# nrf54lv10a_enga_application register map
Vendor: Nordic Semiconductor; Series: nrf54l; File version: 1
CPU: CM33 r0p4, little endian, MPU, FPU, 3 interrupt priority bits, 270 interrupts, 4 SAU regions
Registers are 32-bit, read-write, reset 0x0 unless marked. A register's access mark holds for its fields unless they carry their own. Offsets are from the block's base; [hi:lo] are bit positions; lines under a group give offsets from that group; {n}, {i} and the like mark numbered series; 'fields as' and 'values as' point back to an identical list.

## GLOBAL_RRAMC_S — RRAM controller GLITCH detector
Base 0x5004E000; alternate view of GLOBAL_GLITCHDET_S
0x00 TASKS_WAKEUP wo — Wakeup the RRAM from low power mode
  [0] TASKS_WAKEUP
    1=Trigger task
0x04 TASKS_CLRWRITEBUF wo — Clear internal write-buffer
  [0] TASKS_CLRWRITEBUF
    1=Trigger task
0x08 TASKS_COMMITWRITEBUF wo — Commits the data stored in internal write-buffer to RRAM
  [0] TASKS_COMMITWRITEBUF
    1=Trigger task
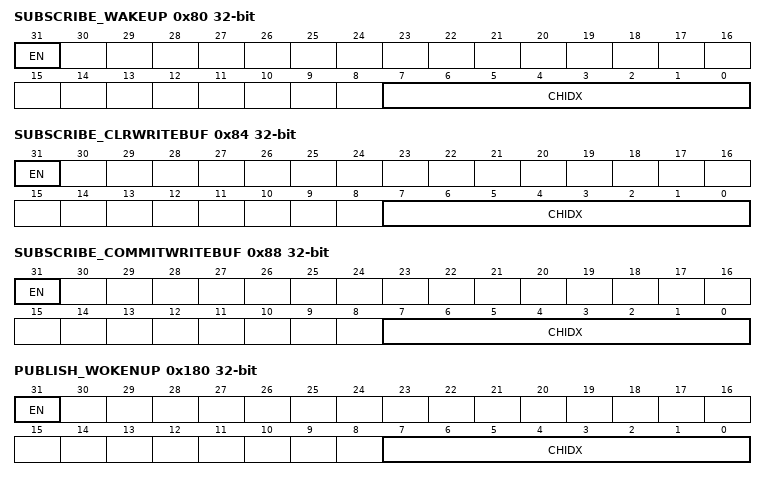
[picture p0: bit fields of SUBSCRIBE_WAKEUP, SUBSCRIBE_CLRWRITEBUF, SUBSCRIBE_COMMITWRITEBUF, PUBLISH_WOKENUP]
0x80 SUBSCRIBE_WAKEUP — Subscribe configuration for task WAKEUP
  [31] EN
    0=Disabled (Disable subscription); 1=Enabled (Enable subscription)
  [7:0] CHIDX — DPPI channel that task WAKEUP will subscribe to
0x84 SUBSCRIBE_CLRWRITEBUF — Subscribe configuration for task CLRWRITEBUF
  [31] EN
    values as SUBSCRIBE_WAKEUP.EN
  [7:0] CHIDX — DPPI channel that task CLRWRITEBUF will subscribe to
0x88 SUBSCRIBE_COMMITWRITEBUF — Subscribe configuration for task COMMITWRITEBUF
  [31] EN
    values as SUBSCRIBE_WAKEUP.EN
  [7:0] CHIDX — DPPI channel that task COMMITWRITEBUF will subscribe to
0x100 EVENTS_WOKENUP — RRAMC is woken up from low power mode
  [0] EVENTS_WOKENUP
    0=NotGenerated (Event not generated); 1=Generated (Event generated)
0x104 EVENTS_READY — RRAMC is ready
  [0] EVENTS_READY
    values as EVENTS_WOKENUP.EVENTS_WOKENUP
0x108 EVENTS_READYNEXT — Ready to accept a new write operation
  [0] EVENTS_READYNEXT
    values as EVENTS_WOKENUP.EVENTS_WOKENUP
0x10C EVENTS_ACCESSERROR — RRAM access error
  [0] EVENTS_ACCESSERROR
    values as EVENTS_WOKENUP.EVENTS_WOKENUP
0x114 EVENTS_ECCERRORCORR — ECC error detected and corrected
  [0] EVENTS_ECCERRORCORR
    values as EVENTS_WOKENUP.EVENTS_WOKENUP
0x180 PUBLISH_WOKENUP — Publish configuration for event WOKENUP
  [31] EN
    0=Disabled (Disable publishing); 1=Enabled (Enable publishing)
  [7:0] CHIDX — DPPI channel that event WOKENUP will publish to
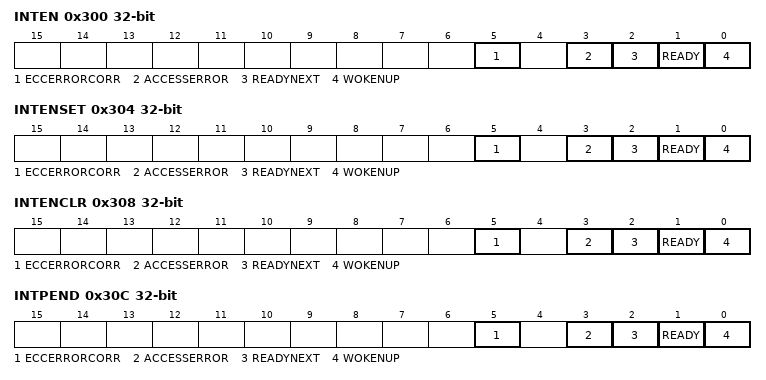
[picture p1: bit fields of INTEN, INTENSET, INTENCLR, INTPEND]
0x300 INTEN — Enable or disable interrupt
  [all] fields
    0=Disabled; 1=Enabled
  [5] ECCERRORCORR — Enable or disable interrupt for event ECCERRORCORR
  [3] ACCESSERROR — Enable or disable interrupt for event ACCESSERROR
  [2] READYNEXT — Enable or disable interrupt for event READYNEXT
  [1] READY — Enable or disable interrupt for event READY
  [0] WOKENUP — Enable or disable interrupt for event WOKENUP
0x304 INTENSET — Enable interrupt
  [all] fields
    on read: 0=Disabled (Read: Disabled); 1=Enabled (Read: Enabled) | on write: 1=Set (Enable)
  [5] ECCERRORCORR — Write '1' to enable interrupt for event ECCERRORCORR
  [3] ACCESSERROR — Write '1' to enable interrupt for event ACCESSERROR
  [2] READYNEXT — Write '1' to enable interrupt for event READYNEXT
  [1] READY — Write '1' to enable interrupt for event READY
  [0] WOKENUP — Write '1' to enable interrupt for event WOKENUP
0x308 INTENCLR — Disable interrupt
  [all] fields
    on read: 0=Disabled (Read: Disabled); 1=Enabled (Read: Enabled) | on write: 1=Clear (Disable)
  [5] ECCERRORCORR — Write '1' to disable interrupt for event ECCERRORCORR
  [3] ACCESSERROR — Write '1' to disable interrupt for event ACCESSERROR
  [2] READYNEXT — Write '1' to disable interrupt for event READYNEXT
  [1] READY — Write '1' to disable interrupt for event READY
  [0] WOKENUP — Write '1' to disable interrupt for event WOKENUP
0x30C INTPEND ro — Pending interrupts
  [all] fields
    on read: 0=NotPending (Read: Not pending); 1=Pending (Read: Pending)
  [5] ECCERRORCORR — Read pending status of interrupt for event ECCERRORCORR
  [3] ACCESSERROR — Read pending status of interrupt for event ACCESSERROR
  [2] READYNEXT — Read pending status of interrupt for event READYNEXT
  [1] READY — Read pending status of interrupt for event READY
  [0] WOKENUP — Read pending status of interrupt for event WOKENUP
0x400 READY ro — RRAMC ready status
  [0] READY — RRAMC is ready or busy
    0=Busy (RRAMC is busy); 1=Ready (The current RRAMC operation is completed and RRAMC is ready)
0x404 READYNEXT ro — Ready next flag
  [0] READYNEXT — RRAMC can accept a new write operation
    0=Busy (RRAMC cannot accept any write operation now); 1=Ready (RRAMC is ready to accept a new write operation)
0x408 ACCESSERRORADDR ro reset 0xFFFFFF — Address of the first access error
  [31:0] ADDRESS — Access error address
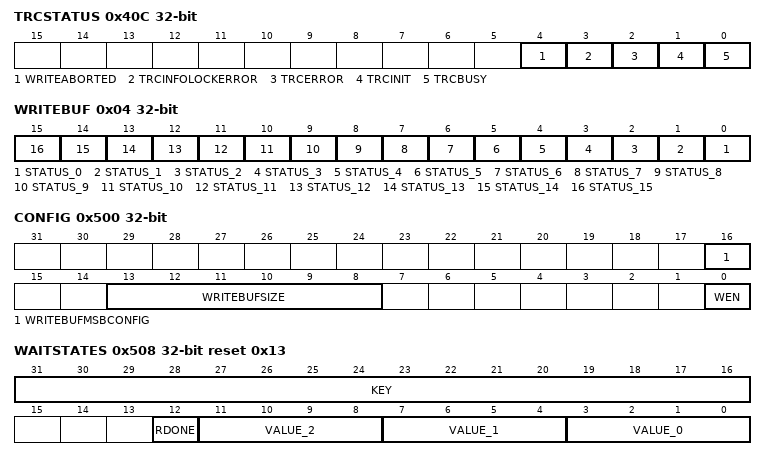
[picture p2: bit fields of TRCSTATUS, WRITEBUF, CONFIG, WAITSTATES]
0x40C TRCSTATUS ro
  [4] WRITEABORTED — Write aborted by unexpected TRC error or POF warning
    0=NotAborted (Write not aborted); 1=Aborted (Write aborted)
  [3] TRCINFOLOCKERROR — TRC info lock error status
    0=NoError (Error not detected); 1=Error detected
  [2] TRCERROR — TRC error status
    0=NoError (Error not detected); 1=Error detected
  [1] TRCINIT — Current TRC initialization or re-initialization status
    0=NotDone (TRC initialization or re-initialization is not done); 1=Done (TRC initialization or re-initialization is done)
  [0] TRCBUSY — Current TRC busy status
    0=NotBusy (TRC is not busy); 1=Busy (TRC is busy)
0x410 BUFSTATUS group — Unspecified
  0x00 LOADBUF ro — Load-buffer status
    [6:0] WORDS — Number of 128-bit RRAM words written into load-buffer that are not committed to RRAM
  0x04 WRITEBUF ro — Write-buffer status
    [n] STATUS_{n} (n=0..15) — Write status for byte [{n}] in write-buffer
      0=NotWriten (Byte [{n}] in write-buffer is not written); 1=Written (Byte [{n}] in write-buffer is written and not committed to load-buffer)
  0x08 WRITEBUFEMPTY ro — Internal write-buffer is empty
    [0] EMPTY
      0=NotEmpty (The internal write-buffer has data that needs committing); 1=Empty (The internal write-buffer is empty and has no content that needs to be committed)
0x420 ECC group — Unspecified
  0x00 ERRORADDR ro reset 0xFFFFFF — Address of the first ECC error that could not be corrected
    [31:0] ADDRESS — ECC error address
  0x04 CORRADDR ro reset 0xFFFFFF — Address of the first ECC error that was corrected
    [31:0] ADDRESS — Address of the ECC error that was corrected
0x500 CONFIG — Configuration register
  [16] WRITEBUFMSBCONFIG — Configuration of writing the write buffer into load buffer when writing to the most significant byte in the current RRAM word
    0=Automatically writes the write buffer into load buffer; 1=NotAutomatic (Writing the write buffer into load buffer is not done automatically)
  [13:8] WRITEBUFSIZE — write-buffer size in number of 128-bit words
    0=Unbuffered (Disable buffering)
  [0] WEN — Write enable
    0=Disabled (Write is disabled); 1=Enabled (Write is enabled)
0x504 READCONFIG — Read configuration register
  [0] READMODE — Configure read mode
    0=DirectRead (RRAMC handles the reads from the RRAM); 1=NormalRead (Deprecated enumerator - Reads using RRAM Soft-IP)
0x508 WAITSTATES reset 0x13 — Waitstates for RRAM read access
  [31:16] KEY wo — Key to enable the writing to this register
    0=Disable the writing to this register; 0xA66D=Enable the writing to this register
  [12] RDONE — Use RDONE (read done) signal from the RRAM macro in addition to waitstates specified above. The data is read after RDONE signal is set, regardless of waitstates value.
    0=Disable (Do not use RDONE signal from the RRAM macro); 1=Enable (Use RDONE signal from the RRAM macro)
  [11:8] VALUE_2 — Waitstates value for frequency index [2]
  [7:4] VALUE_1 — Waitstates value for frequency index [1]
  [3:0] VALUE_0 — Waitstates value for frequency index [0]
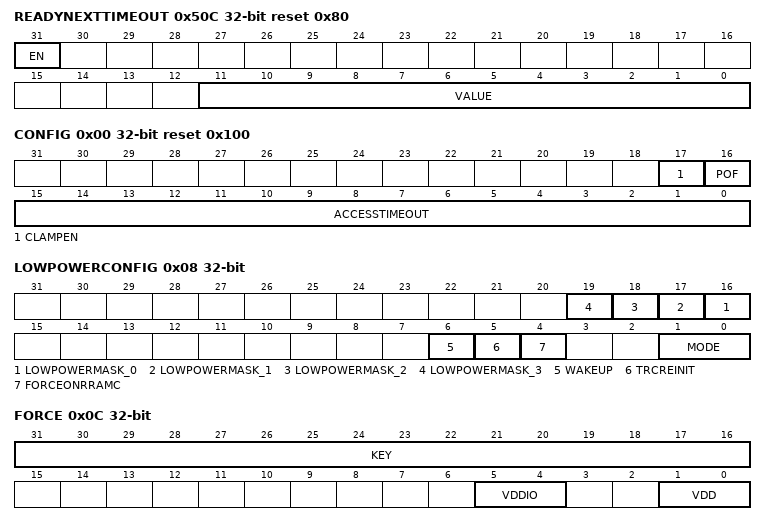
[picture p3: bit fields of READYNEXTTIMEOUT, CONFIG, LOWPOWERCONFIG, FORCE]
0x50C READYNEXTTIMEOUT reset 0x80 — Configuration for ready next timeout counter, in units of AXI clock frequency
  [31] EN — Enable ready next timeout
    0=Disable ready next timeout; 1=Enable ready next timeout
  [11:0] VALUE — Preload value for waiting for a next write
0x510 POWER group — Unspecified
  0x00 CONFIG reset 0x100 — Power configuration
    [17] CLAMPEN — Clamp RRAM VDD to GND during RRAM power-off
      0=Disabled (Clamp is disabled); 1=Enabled (Clamp is enabled)
    [16] POF — Power on failure warning handling configuration
      0=Wait until the current RRAM write finishes; 1=Abort the current RRAM write
    [15:0] ACCESSTIMEOUT — Access timeout, in 31.25 ns units, used for going into standby power mode or remain active on wake up
  0x04 STANDBYCONFIG — Standby mode configuration
    [1:0] MODE — RRAM standby mode
      0=Normal (The RRAM automatically goes into idle mode while the RRAM is not being accessed); 1=NAP (The RRAM goes into NAP mode when the access timeout counter is expired); 2=PowerDown (The RRAM goes into power down mode when the access timeout counter is expired); 3=Standby (The RRAM automatically goes into standby mode while the RRAM is not being accessed)
  0x08 LOWPOWERCONFIG — Low power mode configuration
    [n+16] LOWPOWERMASK_{n} (n=0..3) — Mask for low power mode and wakeup
      0=Unmask (Consumer [{n}] can request going into low power mode and wakeup); 1=Mask (Consumer [{n}] request going into low power mode is ignored)
    [6] WAKEUP — RRAM wakeup configuration
      0=AXI (Wakeup RRAM on the first AXI transaction to the RRAM); 1=CPU (Wakeup RRAM when the CPU wakes up from sleep)
    [5] TRCREINIT — TRC re-initialization configuration during wakeup from RRAMC low power mode
      0=Disabled (TRC re-initialization is disabled during wakeup); 1=Enabled (TRC re-initialization is enabled during wakeup)
    [4] FORCEONRRAMC — Force the RRAMC power domain On
      0=Off (The RRAMC power request is inactive); 1=On (The RRAMC power request is active)
    [1:0] MODE — RRAM low power mode
      0=PowerDown (The RRAM goes into power down mode); 1=Standby (The RRAM automatically goes into standby mode while the RRAM is not being accessed); 2=NAP (The RRAM goes into NAP mode); 3=PowerOff (The RRAM is powered Off)
  0x0C FORCE — Force the power switches to the RRAM On or Off
    [31:16] KEY wo — Key to enable the writing to this register
      values as WAITSTATES.KEY
    [5:4] VDDIO — Force VDDIO to the RRAM On/Off
      0=NoOperation (No request to force VDDIO); 1=On (Force VDDIO On); 2=Off (Force VDDIO Off)
    [1:0] VDD — Force VDD to the RRAM On/Off
      0=NoOperation (No request to force VDD); 1=On (Force VDD On); 2=Off (Force VDD Off)
  0x10 CNT group — Counter/timing configuration for 32 MHz frequency
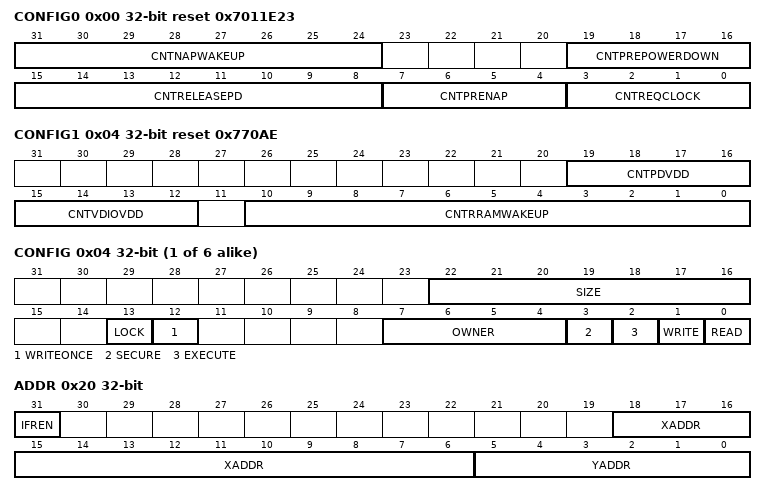
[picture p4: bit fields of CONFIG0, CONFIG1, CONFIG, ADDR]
    0x00 CONFIG0 reset 0x7011E23 — Counter timing configuration CONFIG0
      [31:24] CNTNAPWAKEUP — Counter for NAP wakeup - CNT_NAP_WAKE_UP
      [19:16] CNTPREPOWERDOWN — Counter for pre-power down - CNT_PRE_POWER_DOWN
      [15:8] CNTRELEASEPD — Counter for release power request - CNT_RELEASE_PD
      [7:4] CNTPRENAP — Counter for pre-NAP - CNT_PRE_NAP
      [3:0] CNTREQCLOCK — Counter for clock request - CNT_REQ_CLOCK
    0x04 CONFIG1 reset 0x770AE — Counter timing configuration CONFIG1
      [19:16] CNTPDVDD — Counter used to generate PD pulse during power off (tHO_PD_VDD)
      [15:12] CNTVDIOVDD — Counter used for setup time from IO power (VDIO) to core power (VDD) of RRAM (tSU_IO_CORE)
      [10:0] CNTRRAMWAKEUP — Counter for RRAM wakeup - CNT_RRAM_WAKE_UP
  0x20 STATE ro — State of the Power control FSM
    [5:0] STATE
      0=Start (Unspecified); 1=ReqPowerVDIO (Unspecified); 2=VdIoVddSu (Unspecified); 3=ReqPowerVdd (Unspecified); 4=PowerReady (Unspecified); 5=ReqClock (Unspecified); 6=PdRstSu (Unspecified); 7=ReleaseRst (Unspecified); 8=RramWakeup (Unspecified); 9=TrcInit (Unspecified); 10=InfoPageReadout (Unspecified); 11=Standby (Unspecified); 12=Idle (Unspecified); 13=PrePowerDown (Unspecified); 14=PdPulse (Unspecified); 15=PrePowerOff (Unspecified); 16=PreNap (Unspecified); 17=PowerDown (Unspecified); 18=PowerOff (Unspecified); 19=Nap (Unspecified); 20=FullWakeup (Unspecified); 21=WakeupNap (Unspecified); 22=WakeUpDown (Unspecified); 23=AbortWrite (Unspecified)
0x540 ERASE group — Unspecified
  0x00 ERASEALL — Register for erasing whole RRAM main block, that includes the SICR and the UICR
    [0] ERASE — Erase whole RRAM main block
      0=NoOperation; 1=Erase (Start erase of chip)
  0x04 MASSERASE — Register for erasing the whole RRAM including SICR, UICR and FICR
    [0] ERASE — Erase whole RRAM
      0=NoOperation; 1=Erase (Start mass erase)
{0x550+8i} REGION[{i}] (i=0..5) group — RRAMC can apply access privileges to regions of the RRAM. Some regions are dedicated for system use and are not available for configuration - refer to the instantiation table for details.
  0x00 ADDRESS — Description cluster: Region address
    [31:0] STARTADDR — Start address of the region [n]
  0x04 CONFIG — Description cluster: Region configuration
    [22:16] SIZE — Size in KBytes of region [n]
    [13] LOCK write-1-sets — Enable lock
      0=Disabled (Lock disabled for region [n]); 1=Enabled (Lock enabled for region [n])
    [12] WRITEONCE
      0=Disabled (Write-once disabled); 1=Enabled (Write-once enabled)
    [7:4] OWNER — Owner ID
      0=NotEnforced (Owner ID protection is not enforced)
    [3] SECURE — Secure access
      0=NonSecure (Both Secure and non-Secure access to override region [n] is allowed); 1=Secure (Only secure access to override region [n] is allowed)
    [2] EXECUTE — Execute access
      0=NotAllowed (Execute access to override region [n] is not allowed); 1=Allowed (Execute access to override region [n] is allowed)
    [1] WRITE — Write access
      0=NotAllowed (Write access to override region [n] is not allowed); 1=Allowed (Write access to override region [n] is allowed)
    [0] READ — Read access
      0=NotAllowed (Read access to override region [n] is not allowed); 1=Allowed (Read access to override region [n] is allowed)
0x5D0 INTERNAL group — Unspecified
  {0x0+0x10*j} DFTENABLE[{j}] (j=0..1) group — Unspecified
    {0x0+4k} REG[{k}] (k=0..3) — Description collection: Shadow registers holding the 128-bit data read from FICR.DFTENABLE[n]
      [31:0] DATA ro — Data at REG[o]
0x600 TEST group — Unspecified
  0x00 TESTMODE — Register for entering test mode
    [15:0] MODE
      on read: 0=NORMAL (Read: Not in test-mode); 1=TESTMODE1 (Read: In TESTMODE1); 2=TESTMODE2 (Read: In TESTMODE2) | on write: 0=SetNORMAL (Write: Sets NORMAL mode); 0xBCDE=SetTESTMODE1 (Write: Sets TESTMODE1. Enables the MASSERASE); 0xABCD=SetTESTMODE2 (Write: Sets TESTMODE2. Used for direct control of TRC)
0x610 TESTMODE2 group — Unspecified
  {0xC+4j} DATA[{j}] (j=0..4) — Description collection: Data in/out of TRC register
    [31:0] VAL — Data[m] from/to TRC register
  0x20 ADDR — Address bits of TRC
    [31] IFREN — IFREN (access to info page) line of TRC
    [18:6] XADDR — X-ADDR lines of TRC
    [5:0] YADDR — Y-ADDR lines of TRC
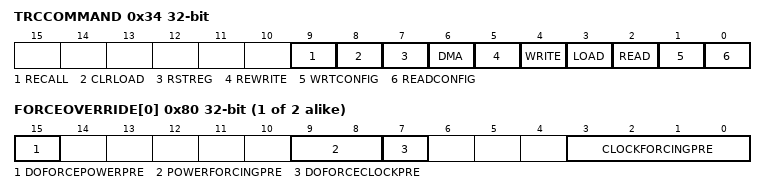
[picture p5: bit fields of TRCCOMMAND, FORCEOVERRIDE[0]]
  0x34 TRCCOMMAND — Test register trigger for TESTREGDATA/ADDR registers
    [9] RECALL — Trigger RECALL
    [8] CLRLOAD — Trigger CLR_LOAD
    [7] RSTREG — Trigger RST_REG
    [6] DMA — Trigger DMA
    [5] REWRITE — Trigger REWRITE
    [4] WRITE — Trigger WRITE
    [3] LOAD — Trigger LOAD
    [2] READ — Trigger read
    [1] WRTCONFIG — Trigger WRT_CONFIG
    [0] READCONFIG — Trigger READ_CONFIG
0xC00 PCGCSLAVE group — Unspecified
  {0x0+4j} PENALTY[{j}] (j=0..1) — Description collection: Penalty level for power/clock pair n
    [7:0] PENALTY — Penalty level
  {0x80+4j} FORCEOVERRIDE[{j}] (j=0..1) — Description collection: Force override of power/clock pair n
    [15] DOFORCEPOWERPRE, [9:8] POWERFORCINGPRE, [7] DOFORCECLOCKPRE, [3:0] CLOCKFORCINGPRE
